VERSION ""

NS_ :

BS_:

BU_: IVT_S FSG_Logger IMU_R SMU_RR RCU SMU_RL GPS_R

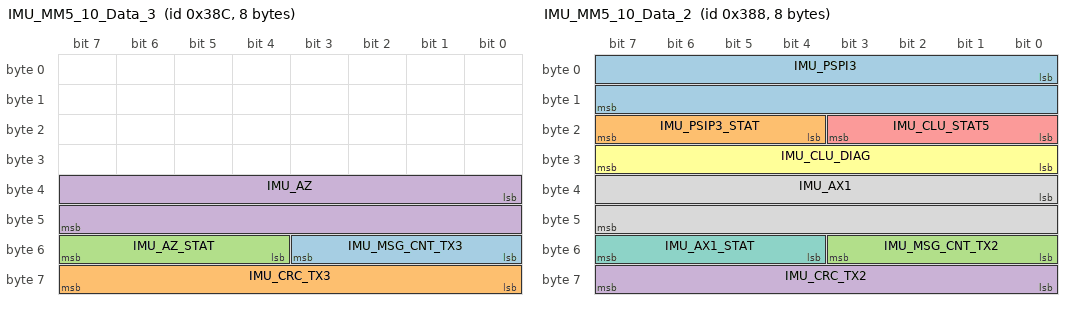
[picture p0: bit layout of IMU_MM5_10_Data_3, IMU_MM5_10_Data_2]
BO_ 908 IMU_MM5_10_Data_3: 8 IMU_R
 SG_ IMU_MSG_CNT_TX3 : 48|4@1+ (1,0) [0|15] "" Vector__XXX
 SG_ IMU_CRC_TX3 : 56|8@1+ (1,0) [0|255] "" Vector__XXX
 SG_ IMU_AZ_STAT : 52|4@1+ (1,0) [0|15] "" Vector__XXX
 SG_ IMU_AZ : 32|16@1+ (0.000127465,-4.1768) [-4.1768|4.1765] "g" Vector__XXX

BO_ 904 IMU_MM5_10_Data_2: 8 IMU_R
 SG_ IMU_PSPI3 : 0|16@1+ (0.005,-163.84) [-163.84|163.835] "°/s" Vector__XXX
 SG_ IMU_PSIP3_STAT : 20|4@1+ (1,0) [0|15] "" Vector__XXX
 SG_ IMU_MSG_CNT_TX2 : 48|4@1+ (1,0) [0|15] "" Vector__XXX
 SG_ IMU_CRC_TX2 : 56|8@1+ (1,0) [0|255] "" Vector__XXX
 SG_ IMU_CLU_STAT5 : 16|4@1+ (1,0) [0|15] "" Vector__XXX
 SG_ IMU_CLU_DIAG : 24|8@1+ (1,0) [0|255] "" Vector__XXX
 SG_ IMU_AX1_STAT : 52|4@1+ (1,0) [0|0] "" Vector__XXX
 SG_ IMU_AX1 : 32|16@1+ (0.000127465,-4.1768) [-4.1768|4.1765] "g" Vector__XXX

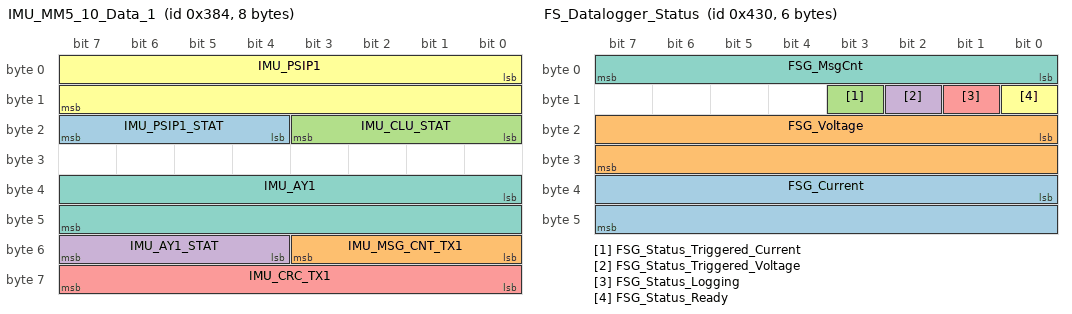
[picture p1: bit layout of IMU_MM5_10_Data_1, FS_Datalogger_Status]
BO_ 900 IMU_MM5_10_Data_1: 8 IMU_R
 SG_ IMU_PSIP1_STAT : 20|4@1+ (1,0) [0|15] "" Vector__XXX
 SG_ IMU_MSG_CNT_TX1 : 48|4@1+ (1,0) [0|15] "" Vector__XXX
 SG_ IMU_CLU_STAT : 16|4@1+ (1,0) [0|15] "" Vector__XXX
 SG_ IMU_AY1_STAT : 52|4@1+ (1,0) [0|15] "" Vector__XXX
 SG_ IMU_CRC_TX1 : 56|8@1+ (1,0) [0|255] "" Vector__XXX
 SG_ IMU_PSIP1 : 0|16@1+ (0.005,-163.84) [-163.84|163.83] "°/s" Vector__XXX
 SG_ IMU_AY1 : 32|16@1+ (0.000127465,-4.1768) [-4.1768|4.1765] "g" Vector__XXX

BO_ 1877 FS_Datalogger_Reserved_6: 8 FSG_Logger

BO_ 1876 FS_Datalogger_Reserved_5: 8 FSG_Logger

BO_ 1875 FS_Datalogger_Reserved_4: 8 FSG_Logger

BO_ 1874 FS_Datalogger_Reserved_3: 8 FSG_Logger

BO_ 1873 FS_Datalogger_Reserved_2: 8 FSG_Logger

BO_ 1872 FS_Datalogger_Reserved_1: 8 FSG_Logger

BO_ 1072 FS_Datalogger_Status: 6 FSG_Logger
 SG_ FSG_Current : 32|16@1+ (64,0) [0|4194240] "mA" Vector__XXX
 SG_ FSG_Voltage : 16|16@1+ (16,0) [0|1048560] "mV" Vector__XXX
 SG_ FSG_Status_Triggered_Current : 11|1@1- (1,0) [0|0] "" Vector__XXX
 SG_ FSG_Status_Triggered_Voltage : 10|1@1- (1,0) [0|0] "" Vector__XXX
 SG_ FSG_Status_Logging : 9|1@1- (1,0) [0|0] "" Vector__XXX
 SG_ FSG_Status_Ready : 8|1@1- (1,0) [0|0] "" Vector__XXX
 SG_ FSG_MsgCnt : 0|8@1+ (1,0) [0|255] "" Vector__XXX

BA_DEF_ SG_  "GenSigSendType" ENUM  "Cyclic","OnWrite","OnWriteWithRepetition","OnChange","OnChangeWithRepetition","IfActive","IfActiveWithRepetition","NoSigSendType","NotUsed","NotUsed","NotUsed","NotUsed","NotUsed";
BA_DEF_ BO_  "GenMsgILSupport" ENUM  "No","Yes";
BA_DEF_ BO_  "GenMsgSendType2" ENUM  "Zyklisch","Ereignisgesteuert","dummy","Auf Anfrage";
BA_DEF_ BO_  "GenMsgFastOnStart" INT 10 500;
BA_DEF_ BO_  "GenMsgCycleTimeActive" INT 1 100;
BA_DEF_ BO_  "VFrameFormat" ENUM  "StandardCAN","ExtendedCAN","reserved","reserved","reserved","reserved","reserved","reserved","reserved","reserved","reserved","reserved","reserved","reserved","StandardCAN_FD","ExtendedCAN_FD";
BA_DEF_ BO_  "GenMsgSendType" ENUM  "Cyclic","NotUsed","NotUsed","NotUsed","NotUsed","NotUsed","NotUsed","IfActive","NoMsgSendType","NotUsed","vector_leerstring";
BA_DEF_  "BusType" STRING ;
BA_DEF_DEF_  "GenSigSendType" "Cyclic";
BA_DEF_DEF_  "GenMsgILSupport" "Yes";
BA_DEF_DEF_  "GenMsgSendType2" "Zyklisch";
BA_DEF_DEF_  "GenMsgFastOnStart" 10;
BA_DEF_DEF_  "GenMsgCycleTimeActive" 10;
BA_DEF_DEF_  "VFrameFormat" "ExtendedCAN_FD";
BA_DEF_DEF_  "GenMsgSendType" "NoMsgSendType";
BA_DEF_DEF_  "BusType" "CAN";
BA_ "VFrameFormat" BO_ 908 0;
BA_ "VFrameFormat" BO_ 904 0;
BA_ "VFrameFormat" BO_ 900 0;
